# NUC200AE_v1 register map
File version: 1.0
Registers are 32-bit, read-write, reset 0x0 unless marked. A register's access mark holds for its fields unless they carry their own. Offsets are from the block's base; [hi:lo] are bit positions; {n}, {i} and the like mark numbered series; 'fields as' and 'values as' point back to an identical list.

## CLK — CLK Register Map
Base 0x50000200
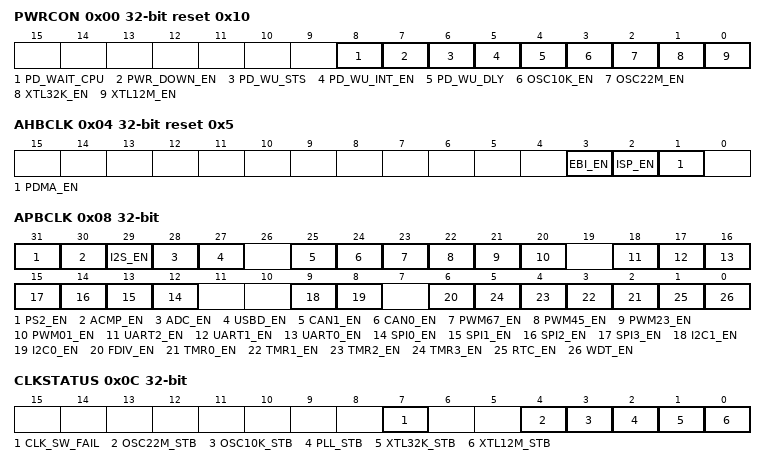
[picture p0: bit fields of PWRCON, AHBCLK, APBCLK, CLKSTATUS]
0x00 PWRCON reset 0x10 (reset mask 0xFFFFFFF0) — System Power-down Control Register
  [8] PD_WAIT_CPU — Power-Down Entry Condition Control (Write Protect). Note: This bit is the protected bit, and programming it needs to write "59h", "16h", and "88h" to address 0x5000_0100 to disable register protection. Refer to the register REGWRPROT at address GCR_BA+0x100.
    0=Chip enters Power-down mode when the PWR_DOWN_EN bit is set to 1; 1=Chip enters Power- down mode when the both PD_WAIT_CPU and PWR_DOWN_EN bits are set to 1 and CPU run WFI instruction
  [7] PWR_DOWN_EN — System Power-Down Enable Bit (Write Protect). When this bit is set to 1, Power-down mode is enabled and chip Power-down behavior will depends on the PD_WAIT_CPU bit (a) If the PD_WAIT_CPU is 0, the chip enters Power-down mode immediately after the PWR_DOWN_EN bit set. (b) if the PD_WAIT_CPU is 1, the chip keeps active till the CPU sleep mode is also active and then the chip enters Power-down mode (recommend). When chip wakes up from Power-down mode, this bit is cleared by hardware. User needs to set this bit again for next Power-down. In Power-down mode, 4~24 MHz external high speed crystal oscillator and the 22.1184 MHz internal high speed RC oscillator will be disabled in this mode, but the 32.768 kHz external low speed crystal oscillator and 10 kHz internal low speed oscillator are not controlled by Power-down mode. In Power- down mode, the PLL and system clock are disabled, and ignored the clock source selection. The clocks of peripheral are not controlled by Power-down mode, if the peripheral clock source is from 32.768 kHz external low speed crystal oscillator or the internal 10 kHz low speed oscillator. Note: This bit is the protected bit, and programming it needs to write "59h", "16h", and "88h" to address 0x5000_0100 to disable register protection. Refer to the register REGWRPROT at address GCR_BA+0x100.
    0=Chip operating normally or chip in Idle mode because of WFI command; 1=Chip enters Power-down mode instantly or waits CPU sleep command WFI
  [6] PD_WU_STS — Power-Down Mode Wake-Up Interrupt Status. Set by "Power-down wake-up event", it indicates that resume from Power-down mode" The flag is set if the GPIO, USB, UART, WDT, I2C, TIMER, ACMP, BOD or RTC wake-up occurred. Write 1 to clear the bit to 0. Note: This bit is working only if PD_WU_INT_EN (PWRCON[5]) set to 1.
  [5] PD_WU_INT_EN — Power-Down Mode Wake-Up Interrupt Enable Bit (Write Protect). Note1: The interrupt will occur when both PD_WU_STS and PD_WU_INT_EN are high. Note2: This bit is the protected bit, and programming it needs to write "59h", "16h", and "88h" to address 0x5000_0100 to disable register protection. Refer to the register REGWRPROT at address GCR_BA+0x100.
    0=Power-down mode wake-up interrupt Disabled; 1=Power-down mode wake-up interrupt Enabled
  [4] PD_WU_DLY — Wake-Up Delay Counter Enable Bit (Write Protect). When the chip wakes up from Power-down mode, the clock control will delay certain clock cycles to wait system clock stable. The delayed clock cycle is 4096 clock cycles when chip work at external 4~24 MHz high speed crystal, and 256 clock cycles when chip work at internal 22.1184 MHz high speed oscillator. Note: This bit is the protected bit, and programming it needs to write "59h", "16h", and "88h" to address 0x5000_0100 to disable register protection. Refer to the register REGWRPROT at address GCR_BA+0x100.
    0=Clock cycles delay Disabled; 1=Clock cycles delay Enabled
  [3] OSC10K_EN — 10 KHz Internal Low Speed RC Oscillator (LIRC) Enable Bit (Write Protect). Note: This bit is the protected bit, and programming it needs to write "59h", "16h", and "88h" to address 0x5000_0100 to disable register protection. Refer to the register REGWRPROT at address GCR_BA+0x100.
    0=10 kHz internal low speed RC oscillator (LIRC) Disabled; 1=10 kHz internal low speed RC oscillator (LIRC) Enabled
  [2] OSC22M_EN — 22.1184 MHz Internal High Speed RC Oscillator (HIRC) Enable Bit (Write Protect). Note: This bit is the protected bit, and programming it needs to write "59h", "16h", and "88h" to address 0x5000_0100 to disable register protection. Refer to the register REGWRPROT at address GCR_BA+0x100.
    0=22.1184 MHz internal high speed RC oscillator (HIRC) Disabled; 1=22.1184 MHz internal high speed RC oscillator (HIRC) Enabled
  [1] XTL32K_EN — 32.768 KHz External Low Speed Crystal Oscillator (LXT) Enable Bit (Write Protect). Note: This bit is the protected bit, and programming it needs to write "59h", "16h", and "88h" to address 0x5000_0100 to disable register protection. Refer to the register REGWRPROT at address GCR_BA+0x100.
    0=32.768 kHz external low speed crystal oscillator (LXT) Disabled; 1=32.768 kHz external low speed crystal oscillator (LXT) Enabled (Normal operation)
  [0] XTL12M_EN — 4~24 MHz External High Speed Crystal Oscillator (HXT) Enable Bit (Write Protect). The bit default value is set by flash controller user configuration register CONFIG0 [26:24]. When the default clock source is from 4~24 MHz external high speed crystal oscillator, this bit is set to 1 automatically. Note: This bit is the protected bit, and programming it needs to write "59h", "16h", and "88h" to address 0x5000_0100 to disable register protection. Refer to the register REGWRPROT at address GCR_BA+0x100.
    0=4 ~ 24 MHz external high speed crystal oscillators (HXT) Disabled; 1=4~24 MHz external high speed crystal oscillator (HXT) Enabled
0x04 AHBCLK reset 0x5 — AHB Devices Clock Enable Control Register
  [3] EBI_EN — EBI Controller Clock Enable Control
    0=EBI engine clock Disabled; 1=EBI engine clock Enabled
  [2] ISP_EN — Flash ISP Controller Clock Enable Bit
    0=Flash ISP peripherial clock Disabled; 1=Flash ISP peripherial clock Enabled
  [1] PDMA_EN — PDMA Controller Clock Enable Bit
    0=PDMA peripherial clock Disabled; 1=PDMA peripherial clock Enabled
0x08 APBCLK (reset mask 0xFFFFFFF0) — APB Devices Clock Enable Control Register
  [31] PS2_EN — PS/2 Clock Enable Bit
    0=PS/2 clock Disabled; 1=PS/2 clock Enabled
  [30] ACMP_EN — Analog Comparator Clock Enable Bit
    0=Analog Comparator clock Disabled; 1=Analog Comparator clock Enabled
  [29] I2S_EN — I2S Clock Enable Bit
    0=I2S clock Disabled; 1=I2S clock Enabled
  [28] ADC_EN — Analog-Digital-Converter (ADC) Clock Enable Bit
    0=ADC clock Disabled; 1=ADC clock Enabled
  [27] USBD_EN — USB 2.0 FS Device Controller Clock Enable Bit
    0=USB clock Disabled; 1=USB clock Enabled
  [25] CAN1_EN — CAN Bus Controller-1 Clock Enable Bit
    0=CAN1 clock Disable; 1=CAN1 clock Enabled
  [24] CAN0_EN — CAN Bus Controller-0 Clock Enable Bit
    0=CAN0 clock Disabled; 1=CAN0 clock Enable
  [23] PWM67_EN — PWM_67 Clock Enable Bit
    0=PWM67 clock Disabled; 1=PWM67 clock Enabled
  [22] PWM45_EN — PWM_45 Clock Enable Bit
    0=PWM45 clock Disabled; 1=PWM45 clock Enabled
  [21] PWM23_EN — PWM_23 Clock Enable Bit
    0=PWM23 clock Disabled; 1=PWM23 clock Enabled
  [20] PWM01_EN — PWM_01 Clock Enable Bit
    0=PWM01 clock Disabled; 1=PWM01 clock Enabled
  [18] UART2_EN — UART2 Clock Enable Bit
    0=UART2 clock Disabled; 1=UART2 clock Enabled
  [17] UART1_EN — UART1 Clock Enable Bit
    0=UART1 clock Disabled; 1=UART1 clock Enabled
  [16] UART0_EN — UART0 Clock Enable Bit
    0=UART0 clock Disabled; 1=UART0 clock Enabled
  [n+12] SPI{n}_EN (n=0..3) — SPI{n} Clock Enable Bit
    0=SPI{n} clock Disabled; 1=SPI{n} clock Enabled
  [9] I2C1_EN — I2C1 Clock Enable Bit
    0=I2C1 clock Disabled; 1=I2C1 clock Enabled
  [8] I2C0_EN — I2C0 Clock Enable Bit
    0=I2C0 clock Disabled; 1=I2C0 clock Enabled
  [6] FDIV_EN — Frequency Divider Output Clock Enable Bit
    0=FDIV clock Disabled; 1=FDIV clock Enabled
  [n+2] TMR{n}_EN (n=0..3) — Timer{n} Clock Enable Bit
    0=Timer{n} clock Disabled; 1=Timer{n} clock Enabled
  [1] RTC_EN — Real-Time-Clock APB Interface Clock Enable Bit. This bit is used to control the RTC APB clock only, The RTC peripheral clock source is selected from RTC_SEL_10K(CLKSEL2[18]). It can be selected to the 32.768 kHz external low speed crystal oscillator or 10 kHz internal low speed RC oscillator.
    0=RTC clock Disabled; 1=RTC clock Enabled
  [0] WDT_EN — Watchdog Timer Clock Enable Bit (Write Protect). Note: This bit is the protected bit, and programming it needs to write "59h", "16h", and "88h" to address 0x5000_0100 to disable register protection. Refer to the register REGWRPROT at address GCR_BA+0x100.
    0=Watchdog Timer clock Disabled; 1=Watchdog Timer clock Enabled
0x0C CLKSTATUS (reset mask 0xFFFFFF00) — Clock Status Monitor Register
  [7] CLK_SW_FAIL ro — Clock Switching Fail Flag (Read Only). This bit is an index that if current system clock source is match as user defined at HCLK_S (CLKSEL[2:0]). When user switch system clock, the system clock source will keep old clock until the new clock is stable. During the period that waiting new clock stable, this bit will be an index shows system clock source is not match as user wanted.
    0=Clock switching success; 1=Clock switching failure
  [4] OSC22M_STB ro — 22.1184 MHz Internal High Speed RC Oscillator (HIRC) Clock Source Stable Flag (Read Only)
    0=22.1184 MHz internal high speed RC oscillator (HIRC) clock is not stable or disabled; 1=22.1184 MHz internal high speed RC oscillator (HIRC) clock is stable and enabled
  [3] OSC10K_STB ro — Internal 10 KHz Low Speed Oscillator (LIRC) Clock Source Stable Flag (Read Only)
    0=10 kHz internal low speed RC oscillator (LIRC) clock is not stable or disabled; 1=10 kHz internal low speed RC oscillator (LIRC) clock is stable and enabled
  [2] PLL_STB ro — Internal PLL Clock Source Stable Flag (Read Only)
    0=Internal PLL clock is not stable or disabled; 1=Internal PLL clock is stable in normal mode
  [1] XTL32K_STB ro — 32.768 KHz External Low Speed Crystallator Oscillator (LXT) Clock Source Stable Flag (Read Only)
    0=32.768 kHz external low speed crystal oscillator (LXT) clock is not stable or disabled; 1=32.768 kHz external low speed crystal oscillator (LXT) clock is stable and enabled
  [0] XTL12M_STB ro — 4~24 MHz External High Speed Crystal Oscillator (HXT) Clock Source Stable Flag (Read Only)
    0=4~24 MHz external high speed crystal oscillator (HXT) clock is not stable or disabled; 1=4~24 MHz external high speed crystal oscillator (HXT) clock is stable and enabled
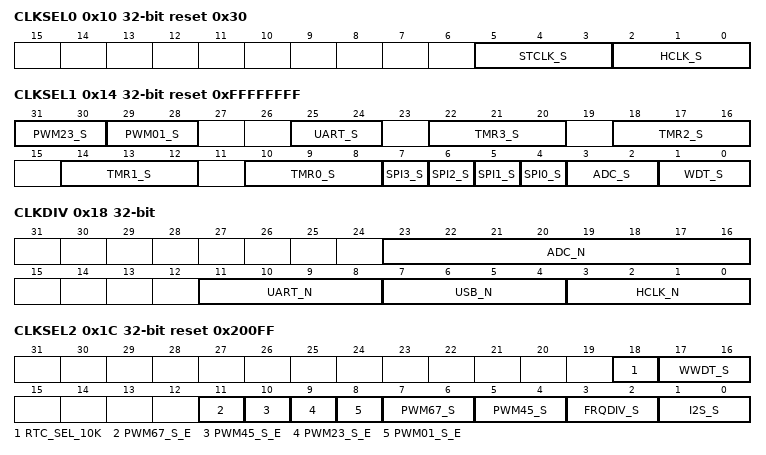
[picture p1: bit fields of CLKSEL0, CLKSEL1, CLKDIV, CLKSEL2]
0x10 CLKSEL0 reset 0x30 (reset mask 0xFFFFFFF0) — Clock Source Select Control Register 0
  [5:3] STCLK_S — Cortex-M0 SysTick Clock Source Select (Write Protect)
    0=Clock source from 4~24 MHz external high speed crystal oscillator clock; 1=Clock source from 32.768 kHz external low speed crystal oscillator clock; 2=Clock source from 4~24 MHz external high speed crystal oscillator clock/2; 3=Clock source from HCLK/2; 7=Clock source from 22.1184 MHz internal high speed RC oscillator clock/2
  [2:0] HCLK_S — HCLK Clock Source Select (Write Protect). Before clock switching, the related clock sources (both pre-select and new-select) must be enabled. The 3-bit default value is reloaded from the value of CFOSC (CONFIG0[26:24]) in user configuration register of Flash controller by any reset. Therefore the default value is either 000b or 111b. These bits are protected bit, It means programming this bit needs to write "59h", "16h", "88h" to address 0x5000_0100 to disable register protection. Refer to the register REGWRPROT at address GCR_BA+0x100. Note: This bit is the protected bit, and programming it needs to write "59h", "16h", and "88h" to address 0x5000_0100 to disable register protection. Refer to the register REGWRPROT at address GCR_BA+0x100.
    0=Clock source from 4~24 MHz external high speed crystal oscillator clock; 1=Clock source from 32.768 kHz external low speed crystal oscillator clock; 2=Clock source from PLL clock; 3=Clock source from 10 kHz internal low speed RC oscillator clock; 7=Clock source from 22.1184 MHz internalhigh speed RC oscillator clock
0x14 CLKSEL1 reset 0xFFFFFFFF — Clock Source Select Control Register 1
  [31:30] PWM23_S — PWM2 And PWM3 Clock Source Selection. PWM2 and PWM3 used the same peripheral clock source; both of them used the same prescaler. The peripheral clock source of PWM2 and PWM3 is defined by PWM23_S (CLKSEL1[31:30]) and PWM23_S_E (CLKSEL2[9]).
    0=Clock source from 4~24 MHz external high speed crystal oscillator clock. Reserved; 1=Clock source from 32.768 kHz external low speed crystal oscillator clock. Reserved; 2=Clock source from HCLK. Reserved; 3=Clock source from 22.1184 MHz internal high speed RC oscillator clock. Clock source from 10 kHz internal low speed RC oscillator clock
  [29:28] PWM01_S — PWM0 And PWM1 Clock Source Selection. PWM0 and PWM1 used the same peripheral clock source; both of them used the same prescaler. The peripheral clock source of PWM0 and PWM1 is defined by PWM01_S (CLKSEL1[29:28]) and PWM01_S_E (CLKSEL2[8]).
  [25:24] UART_S — UART Clock Source Selection
    0=Clock source from 4~24 MHz external high speed crystal oscillator clock; 1=Clock source from PLL clock; 3=Clock source from 22.1184 MHz internal high speed RC oscillator clock
  [22:20] TMR3_S — TIMER3 Clock Source Selection
    0=Clock source from 4~24 MHz external high speed crystal oscillator clock; 1=Clock source from 32.768 kHz external low speed crystal oscillator clock; 2=Clock source from HCLK; 3=Clock source from external trigger; 5=Clock source from 10 kHz internal low speed RC oscillator clock; 7=Clock source from 22.1184 MHz internal high speed RC oscillator clock
  [18:16] TMR2_S — TIMER2 Clock Source Selection
    0=Clock source from external 4~24 MHz high speed crystal oscillator clock; 1=Clock source from external 32.768 kHz low speed crystal oscillator clock; 2=Clock source from HCLK; 3=Clock source from external trigger; 5=Clock source from internal 10 kHz low speed RC oscillator clock; 7=Clock source from internal 22.1184 MHz high speed RC oscillator clock
  [14:12] TMR1_S — TIMER1 Clock Source Selection
    values as TMR3_S
  [10:8] TMR0_S — TIMER0 Clock Source Selection
    values as TMR3_S
  [n+4] SPI{n}_S (n=0..3) — SPI{n} Clock Source Selection
    0=Clock source from PLL clock; 1=Clock source from HCLK
  [3:2] ADC_S — ADC Clock Source Select
    0=Clock source from 4~24 MHz external high speed crystal oscillator clock; 1=Clock source from PLL clock; 2=Clock source from HCLK; 3=Clock source from 22.1184 MHz internal high speed RC oscillator clock
  [1:0] WDT_S — Watchdog Timer Clock Source Select (Write Protect). Note: This bit is the protected bit, and programming it needs to write "59h", "16h", and "88h" to address 0x5000_0100 to disable register protection. Refer to the register REGWRPROT at address GCR_BA+0x100.
    1=Clock source from 32.768 kHz external low speed crystal oscillator clock; 2=Clock source from HCLK/2048 clock; 3=Clock source from 10 kHz internal low speed RC oscillator clock
0x18 CLKDIV — Clock Divider Number Register
  [23:16] ADC_N — ADC Clock Divide Number From ADC Clock Source
  [11:8] UART_N — UART Clock Divide Number From UART Clock Source
  [7:4] USB_N — USB Clock Divide Number From PLL Clock
  [3:0] HCLK_N — HCLK Clock Divide Number From HCLK Clock Source
0x1C CLKSEL2 reset 0x200FF — Clock Source Select Control Register 2
  [18] RTC_SEL_10K — RTC Clock Source Selection
    0=Clock source from 32.768 kHz external low speed crystal oscillator clock; 1=Clock source from 10 kHz internal low speed RC oscillator clock
  [17:16] WWDT_S — Window Watchdog Timer Clock Source Selection
    2=Clock source from HCLK/2048 clock; 3=Clock source from 10 kHz internal low speed RC oscillator clock
  [11] PWM67_S_E — PWM6 And PWM7 Clock Source Selection Extend. PWM6 and PWM7 used the same peripheral clock source; both of them used the same prescaler. The peripheral clock source of PWM6 and PWM7 is defined by PWM67_S (CLKSEL2[7:6]) and PWM67_S_E (CLKSEL2[11]).
  [10] PWM45_S_E — PWM4 And PWM5 Clock Source Selection Extend. PWM4 and PWM5 used the same peripheral clock source; both of them used the same prescaler. The peripheral clock source of PWM4 and PWM5 is defined by PWM45_S (CLKSEL2[5:4]) and PWM45_S_E (CLKSEL2[10]).
  [9] PWM23_S_E — PWM2 And PWM3 Clock Source Selection Extend. PWM2 and PWM3 used the same peripheral clock source; both of them used the same prescaler. The perpherial clock source of PWM2 and PWM3 is defined by PWM23_S (CLKSEL1[31:30]) and PWM23_S_E (CLKSEL2[9]).
  [8] PWM01_S_E — PWM0 And PWM1 Clock Source Selection Extend. PWM0 and PWM1 used the same peripheral clock source; both of them used the same prescaler. The peripheral clock source of PWM0 and PWM1 is defined by PWM01_S (CLKSEL1[29:28]) and PWM01_S_E (CLKSEL2[8]).
  [7:6] PWM67_S — PWM6 And PWM7 Clock Source Selection. PWM6 and PWM7 used the same peripheral clock source; both of them used the same prescaler. The peripheral clock source of PWM6 and PWM7 is defined by PWM67_S (CLKSEL2[7:6]) and PWM67_S_E (CLKSEL2[11]).
    values as CLKSEL1.PWM23_S
  [5:4] PWM45_S — PWM4 And PWM5 Clock Source Selection. PWM4 and PWM5 used the same peripheral clock source; both of them used the same prescaler. The peripheral clock source of PWM4 and PWM5 is defined by PWM45_S (CLKSEL2[5:4]) and PWM45_S_E (CLKSEL2[10]).
    values as CLKSEL1.PWM23_S
  [3:2] FRQDIV_S — Clock Divider Clock Source Selection
    0=Clock source from 4~24 MHz external high speed crystal oscillator clock; 1=Clock source from 32.768 kHz external low speed crystal oscillator clock; 2=Clock source from HCLK; 3=Clock source from 22.1184 MHz internal high speed RC oscillator clock
  [1:0] I2S_S — I2S Clock Source Selection
    values as CLKSEL1.ADC_S
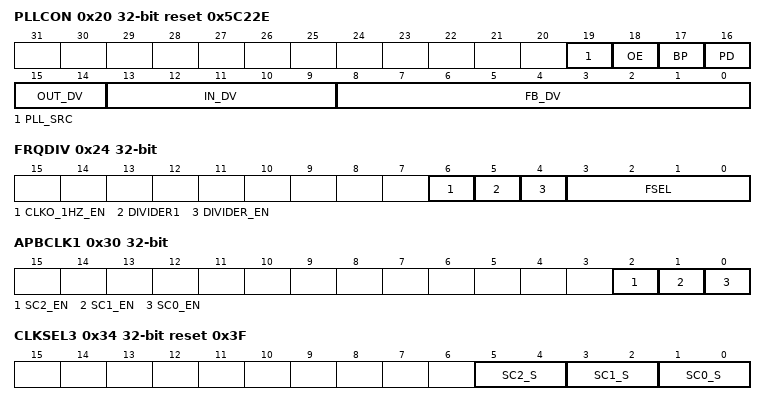
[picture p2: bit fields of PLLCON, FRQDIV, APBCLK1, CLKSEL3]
0x20 PLLCON reset 0x5C22E — PLL Control Register
  [19] PLL_SRC — PLL Source Clock Selection
    0=PLL source clock from 4~24 MHz external high speed crystal oscillator; 1=PLL source clock from 22.1184 MHz internal high speed RC oscillator
  [18] OE — PLL OE (FOUT Enable) Pin Control
    0=PLL FOUT Enabled; 1=PLL FOUT is fixed low
  [17] BP — PLL Bypass Control
    0=PLL is in Normal mode (default); 1=PLL clock output is same as PLL source clock input
  [16] PD — Power-Down Mode. If the PWR_DOWN_EN bit is set to 1 in PWRCON register, the PLL will enter Power-down mode too.
    0=PLL is in Normal mode; 1=PLL is in Power-down mode (default)
  [15:14] OUT_DV — PLL Output Divider Control Bits. Refer to the formulas below the table.
  [13:9] IN_DV — PLL Input Divider Control Bits. Refer to the formulas below the table.
  [8:0] FB_DV — PLL Feedback Divider Control Bits. Refer to the formulas below the table.
0x24 FRQDIV — Frequency Divider Control Register
  [6] CLKO_1HZ_EN — Clock Output 1Hz Enable Bit
    0=1 Hz clock output for 32.768 kHz external low speed crystal oscillator clock frequency compensation Disabled; 1=1 Hz clock output for 32.768 kHz external low speed crystal oscillator clock frequency compensation Enabled
  [5] DIVIDER1 — Frequency Divider One Enable Bit
    0=Frequency divider will output clock with source frequency divided by FSEL; 1=Frequency divider will output clock with source frequency
  [4] DIVIDER_EN — Frequency Divider Enable Bit
    0=Frequency Divider function Disabled; 1=Frequency Divider function Enabled
  [3:0] FSEL — Divider Output Frequency Selection Bits. The formula of output frequency is. Fin is the input clock frequency. Fout is the frequency of divider output clock. N is the 4-bit value of FSEL[3:0].
0x30 APBCLK1 — APB Devices Clock Enable Control Register 1
  [2] SC2_EN — SC2 Clock Enable Bit
    0=SC2 clock Disabled; 1=SC2 clock Enabled
  [1] SC1_EN — SC1 Clock Enable Bit
    0=SC1 clock Disabled; 1=SC1 clock Enabled
  [0] SC0_EN — SC0 Clock Enable Bit
    0=SC0 Clock Disabled; 1=SC0 Clock Enabled
0x34 CLKSEL3 reset 0x3F — Clock Source Select Control Register 3
  [all] fields
    values as CLKSEL1.ADC_S
  [5:4] SC2_S — SC2 Clock Source Selection
  [3:2] SC1_S — SC1 Clock Source Selection
  [1:0] SC0_S — SC0 Clock Source Selection
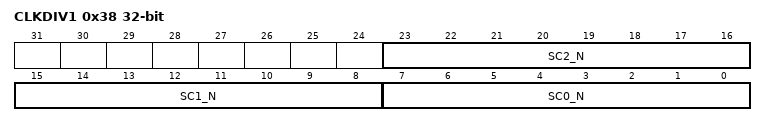
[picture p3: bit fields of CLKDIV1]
0x38 CLKDIV1 — Clock Divider Number Register 1
  [23:16] SC2_N — SC2 Clock Divide Number From SC2 Clock Source
  [15:8] SC1_N — SC1 Clock Divide Number From SC1 Clock Source
  [7:0] SC0_N — SC0 Clock Divide Number From SC0 Clock Source
